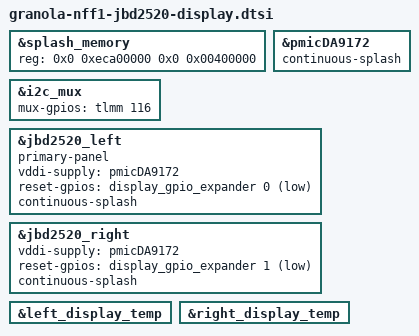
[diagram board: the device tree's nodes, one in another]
// SPDX-License-Identifier: GPL-2.0

#include "granola-jbd2520-display-common.dtsi"
#include "granola-nff1-display-gpios.dtsi"

/*
 * Keep this aligned with UEFI's 4 MiB Display Reserved carveout
 * when ABL does not update the splash node.
 */
&splash_memory {
	reg = <0x0 0xeca00000 0x0 0x00400000>;
};

&i2c_mux {
	mux-gpios = <&tlmm 116 GPIO_ACTIVE_HIGH>;
};

&pmicDA9172 {
	continuous-splash;
};

&jbd2520_left {
	primary-panel;
	vddi-supply = <&pmicDA9172>;

	reset-gpios = <&display_gpio_expander 0 GPIO_ACTIVE_LOW>;

	continuous-splash;
};

&jbd2520_right {
	vddi-supply = <&pmicDA9172>;

	reset-gpios = <&display_gpio_expander 1 GPIO_ACTIVE_LOW>;

	continuous-splash;
};

&left_display_temp {
	status = "okay";
};

&right_display_temp {
	status = "okay";
};
